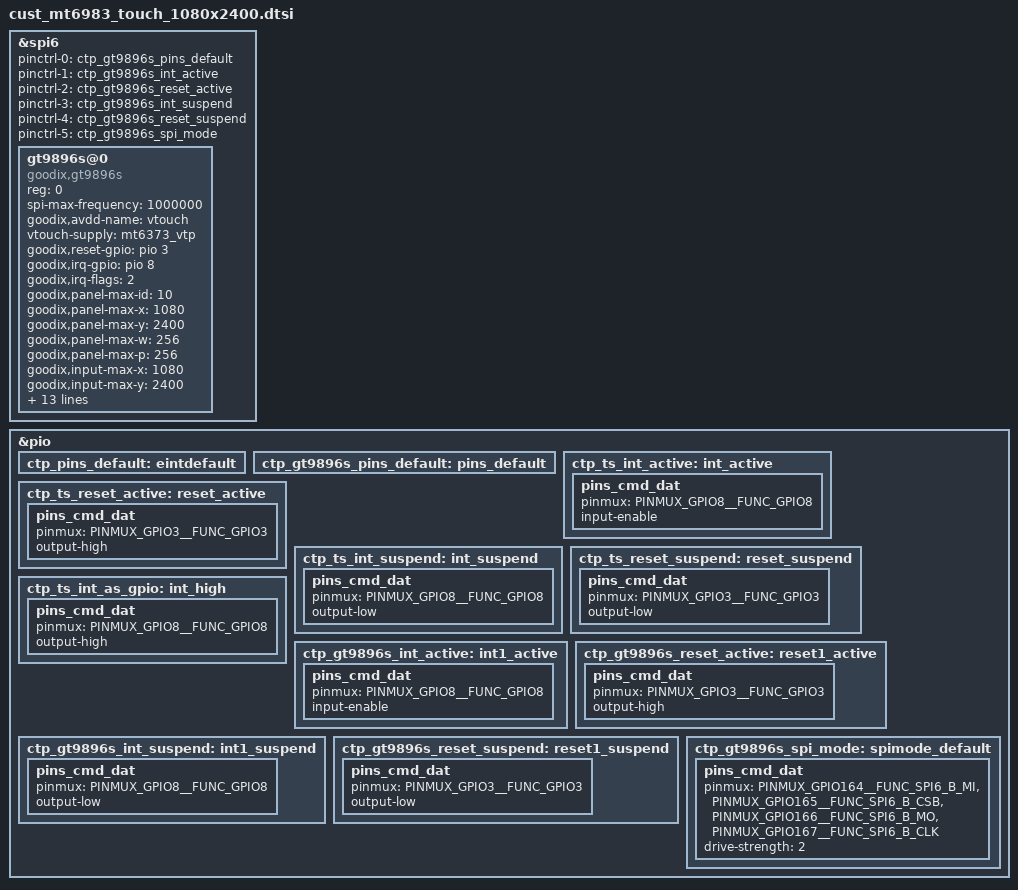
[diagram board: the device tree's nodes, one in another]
// SPDX-License-Identifier: (GPL-2.0 OR MIT)
/*
 * Copyright (C) 2020 MediaTek Inc.
 */

/* TOUCH start */

&spi6 {
	status = "okay";
	#address-cells = <1>;
	#size-cells = <0>;
	pinctrl-names = "default", "gt9896s_int_active",
		"gt9896s_reset_active", "gt9896s_int_suspend",
		"gt9896s_reset_suspend", "gt9896s_spi_mode";
	pinctrl-0 = <&ctp_gt9896s_pins_default>;
	pinctrl-1 = <&ctp_gt9896s_int_active>;
	pinctrl-2 = <&ctp_gt9896s_reset_active>;
	pinctrl-3 = <&ctp_gt9896s_int_suspend>;
	pinctrl-4 = <&ctp_gt9896s_reset_suspend>;
	pinctrl-5 = <&ctp_gt9896s_spi_mode>;

	gt9896s@0 {
		compatible = "goodix,gt9896s";
		reg = <0>; //Same as CS ID
		spi-max-frequency = <1000000>;

		goodix,avdd-name = "vtouch";
		vtouch-supply = <&mt6373_vtp>;
		goodix,reset-gpio = <&pio 3 0x0>;
		goodix,irq-gpio = <&pio 8 0x0>;
		goodix,irq-flags = <2>; /* 1:rising, 2:falling;*/
		goodix,panel-max-id = <10>;
		goodix,panel-max-x = <1080>;
		goodix,panel-max-y = <2400>;
		goodix,panel-max-w = <256>;
		goodix,panel-max-p = <256>;
		goodix,input-max-x = <1080>;
		goodix,input-max-y = <2400>;
		goodix,panel-key-map = <158 172 217>; /*BACK,HOMEPAGE,SEARCH*/
		goodix,power-on-delay-us = <10000>; /*10ms*/
		goodix,power-off-delay-us = <5000>;
		goodix,firmware-version = "6983v01";
		goodix,config-version = "6983v01";
		/*goodix,swap-axis;*/
		goodix,x2x;
		goodix,y2y;
		goodix,pen-enable;
		tpd-filter-enable = <0>;
		tpd-filter-pixel-density = <161>;
		tpd-filter-custom-prameters = <0 0 0 0 0 0 0 0 0 0 0 0>;
		tpd-filter-custom-speed = <0 0 0>;
	};

};

&pio {
	ctp_pins_default: eintdefault {
	};
	ctp_gt9896s_pins_default: pins_default {
	};
	ctp_ts_int_active: int_active {
		pins_cmd_dat {
			pinmux = <PINMUX_GPIO8__FUNC_GPIO8>;
			input-enable;
		};
	};
	ctp_ts_reset_active: reset_active {
		pins_cmd_dat {
			pinmux = <PINMUX_GPIO3__FUNC_GPIO3>;
			output-high;
		};
	};
	ctp_ts_int_suspend: int_suspend {
		pins_cmd_dat {
			pinmux = <PINMUX_GPIO8__FUNC_GPIO8>;
			output-low;
		};
	};
	ctp_ts_reset_suspend: reset_suspend {
		pins_cmd_dat {
			pinmux = <PINMUX_GPIO3__FUNC_GPIO3>;
			output-low;
		};
	};
	ctp_ts_int_as_gpio: int_high {
		pins_cmd_dat {
			pinmux = <PINMUX_GPIO8__FUNC_GPIO8>;
			output-high;
		};
	};
	ctp_gt9896s_int_active: int1_active {
		pins_cmd_dat {
			pinmux = <PINMUX_GPIO8__FUNC_GPIO8>;
			input-enable;
		};
	};
	ctp_gt9896s_reset_active: reset1_active {
		pins_cmd_dat {
			pinmux = <PINMUX_GPIO3__FUNC_GPIO3>;
			output-high;
		};
	};
	ctp_gt9896s_int_suspend: int1_suspend {
		pins_cmd_dat {
			pinmux = <PINMUX_GPIO8__FUNC_GPIO8>;
			output-low;
		};
	};
	ctp_gt9896s_reset_suspend: reset1_suspend {
		pins_cmd_dat {
			pinmux = <PINMUX_GPIO3__FUNC_GPIO3>;
			output-low;
		};
	};
	ctp_gt9896s_spi_mode: spimode_default {
		pins_cmd_dat {
			pinmux = <PINMUX_GPIO164__FUNC_SPI6_B_MI>,
				<PINMUX_GPIO165__FUNC_SPI6_B_CSB>,
				<PINMUX_GPIO166__FUNC_SPI6_B_MO>,
				<PINMUX_GPIO167__FUNC_SPI6_B_CLK>;
			drive-strength = <2>;
		};
	};
};
/* TOUCH end */
